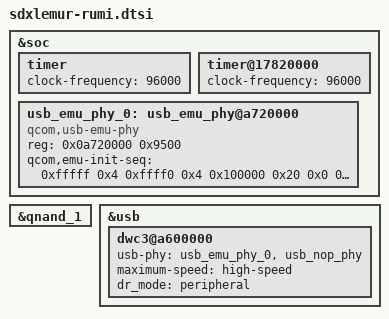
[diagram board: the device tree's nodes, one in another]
#include "sdxlemur-pmic-overlay.dtsi"

&soc {
	timer {
		clock-frequency = <96000>;
	};

	timer@17820000 {
		clock-frequency = <96000>;
	};

	usb_emu_phy_0: usb_emu_phy@a720000 {
		compatible = "qcom,usb-emu-phy";
		reg = <0x0a720000 0x9500>;

		qcom,emu-init-seq = <0xfffff 0x4
				     0xffff0 0x4
				     0x100000 0x20
				     0x0 0x20
				     0x101f0 0x20
				     0x100000 0x3c
				     0x0 0x3c
				     0x10060 0x3c
				     0x0 0x4>;
	};

};

&qnand_1 {
	status = "ok";
};

&usb {
	dwc3@a600000 {
		usb-phy = <&usb_emu_phy_0>, <&usb_nop_phy>;
		maximum-speed = "high-speed";
		dr_mode = "peripheral";
	};
};
